AUTOSAR XML (schema 4-2-2)
package /Components
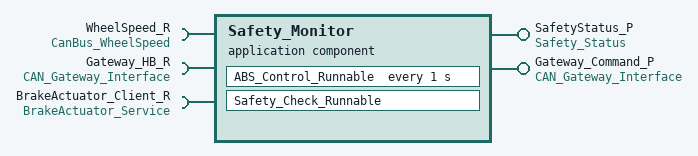
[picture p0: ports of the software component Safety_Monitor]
  application sw component type Safety_Monitor
    provide port SafetyStatus_P: provided-interface=Safety_Status
    provide port Gateway_Command_P: provided-interface=CAN_Gateway_Interface
    require port WheelSpeed_R: required-interface=CanBus_WheelSpeed
    require port Gateway_HB_R: required-interface=CAN_Gateway_Interface
    require port BrakeActuator_Client_R: required-interface=BrakeActuator_Service
    behavior Safety_Monitor_Behavior
      data received event Safety_Input_Update: start-on-event=Process_WheelSpeeds
      swc mode switch event Safety_Mode_Switch: start-on-event=ESP_Control_Runnable, activation=ON, mode=SafetyModeGroup.Gateway_HB_R.SafetyMode
      timing event Safety_Watchdog_1ms: start-on-event=ABS_Control_Runnable, period=1
      runnable Safety_Check_Runnable: minimum-start-interval=1, symbol=Safety_Check_Runnable_Symbol
        data-receive-point-by-arguments:
          5 x access:
            WheelSpeed_FL_Access: accessed-variable=WheelSpeed_R.WheelSpeed_FL
            WheelSpeed_FR_Access: accessed-variable=WheelSpeed_R.WheelSpeed_FR
            WheelSpeed_RL_Access: accessed-variable=WheelSpeed_R.WheelSpeed_RL
            WheelSpeed_RR_Access: accessed-variable=WheelSpeed_R.WheelSpeed_RR
            Controller_Heartbeat_Access: accessed-variable=Gateway_HB_R.Controller_Heartbeat
        async call Reset_Service_Call: operation=BrakeActuator_Client_R.ResetOperation, timeout=10
